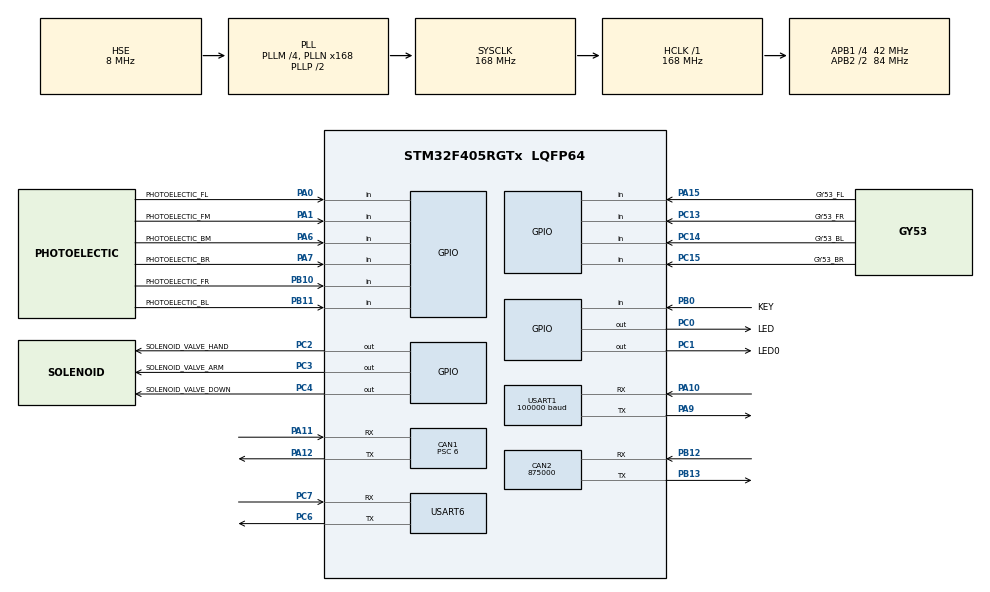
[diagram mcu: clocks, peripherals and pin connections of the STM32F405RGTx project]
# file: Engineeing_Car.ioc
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CAN1.BS1=CAN_BS1_3TQ
CAN1.BS2=CAN_BS2_4TQ
CAN1.CalculateBaudRate=875000
CAN1.CalculateTimeBit=1142.85
CAN1.CalculateTimeQuantum=142.85714285714286
CAN1.Mode=CAN_MODE_NORMAL
CAN1.NART=ENABLE
CAN1.Prescaler=6
CAN1.SJW=CAN_SJW_1TQ
CAN2.CalculateBaudRate=875000
CAN2.CalculateTimeBit=1142.85
CAN2.CalculateTimeQuantum=380.95238095238096
Dma.Request0=USART1_RX
Dma.Request1=USART6_TX
Dma.Request2=USART6_RX
Dma.USART1_RX.0.Direction=DMA_PERIPH_TO_MEMORY
Dma.USART1_RX.0.FIFOMode=DMA_FIFOMODE_DISABLE
Dma.USART1_RX.0.Instance=DMA2_Stream2
Dma.USART1_RX.0.MemDataAlignment=DMA_MDATAALIGN_BYTE
Dma.USART1_RX.0.MemInc=DMA_MINC_ENABLE
Dma.USART1_RX.0.Mode=DMA_NORMAL
Dma.USART1_RX.0.PeriphDataAlignment=DMA_PDATAALIGN_BYTE
Dma.USART1_RX.0.PeriphInc=DMA_PINC_DISABLE
Dma.USART1_RX.0.Priority=DMA_PRIORITY_VERY_HIGH
Dma.USART6_RX.2.Direction=DMA_PERIPH_TO_MEMORY
Dma.USART6_RX.2.FIFOMode=DMA_FIFOMODE_DISABLE
Dma.USART6_RX.2.Instance=DMA2_Stream1
Dma.USART6_RX.2.MemDataAlignment=DMA_MDATAALIGN_BYTE
Dma.USART6_RX.2.MemInc=DMA_MINC_ENABLE
Dma.USART6_RX.2.Mode=DMA_NORMAL
Dma.USART6_RX.2.PeriphDataAlignment=DMA_PDATAALIGN_BYTE
Dma.USART6_RX.2.PeriphInc=DMA_PINC_DISABLE
Dma.USART6_RX.2.Priority=DMA_PRIORITY_LOW
Dma.USART6_TX.1.Direction=DMA_MEMORY_TO_PERIPH
Dma.USART6_TX.1.FIFOMode=DMA_FIFOMODE_DISABLE
Dma.USART6_TX.1.Instance=DMA2_Stream6
Dma.USART6_TX.1.MemDataAlignment=DMA_MDATAALIGN_BYTE
Dma.USART6_TX.1.MemInc=DMA_MINC_ENABLE
Dma.USART6_TX.1.Mode=DMA_NORMAL
Dma.USART6_TX.1.PeriphDataAlignment=DMA_PDATAALIGN_BYTE
Dma.USART6_TX.1.PeriphInc=DMA_PINC_DISABLE
Dma.USART6_TX.1.Priority=DMA_PRIORITY_HIGH
Mcu.Family=STM32F4
Mcu.Name=STM32F405RGTx
Mcu.Package=LQFP64
NVIC.CAN1_RX0_IRQn=true\:1\:0\:true\:false\:true\:true\:true
NVIC.CAN2_RX0_IRQn=true\:0\:0\:false\:false\:true\:true\:true
NVIC.DMA2_Stream1_IRQn=true\:0\:0\:false\:false\:true\:false\:true
NVIC.DMA2_Stream2_IRQn=true\:0\:0\:false\:false\:true\:false\:true
NVIC.DMA2_Stream6_IRQn=true\:0\:0\:false\:false\:true\:false\:true
NVIC.PriorityGroup=NVIC_PRIORITYGROUP_4
NVIC.TIM2_IRQn=true\:0\:0\:false\:false\:true\:true\:true
NVIC.TIM3_IRQn=true\:0\:0\:false\:false\:true\:true\:true
NVIC.TIM4_IRQn=true\:0\:0\:false\:false\:true\:true\:true
PA0-WKUP.GPIO_Label=PHOTOELECTIC_FL
PA0-WKUP.GPIO_PuPd=GPIO_PULLUP
PA0-WKUP.Signal=GPIO_Input
PA1.GPIO_Label=PHOTOELECTIC_FM
PA1.GPIO_PuPd=GPIO_PULLUP
PA1.Signal=GPIO_Input
PA10.Mode=Asynchronous
PA10.Signal=USART1_RX
PA11.Mode=CAN_Activate
PA11.Signal=CAN1_RX
PA12.Mode=CAN_Activate
PA12.Signal=CAN1_TX
PA15.GPIO_Label=GY53_FL
PA15.GPIO_PuPd=GPIO_PULLUP
PA15.Signal=GPIO_Input
PA6.GPIO_Label=PHOTOELECTIC_BM
PA6.GPIO_PuPd=GPIO_PULLUP
PA6.Signal=GPIO_Input
PA7.GPIO_Label=PHOTOELECTIC_BR
PA7.GPIO_PuPd=GPIO_PULLUP
PA7.Signal=GPIO_Input
PA9.Mode=Asynchronous
PA9.Signal=USART1_TX
PB0.GPIO_Label=KEY
PB0.GPIO_PuPd=GPIO_PULLUP
PB0.Signal=GPIO_Input
PB10.GPIO_Label=PHOTOELECTIC_FR
PB10.GPIO_PuPd=GPIO_PULLUP
PB10.Signal=GPIO_Input
PB11.GPIO_Label=PHOTOELECTIC_BL
PB11.GPIO_PuPd=GPIO_PULLUP
PB11.Signal=GPIO_Input
PB12.Mode=CAN_Activate
PB12.Signal=CAN2_RX
PB13.Mode=CAN_Activate
PB13.Signal=CAN2_TX
PC0.GPIO_Label=LED
PC0.GPIO_PuPd=GPIO_PULLDOWN
PC0.GPIO_Speed=GPIO_SPEED_FREQ_HIGH
PC0.PinState=GPIO_PIN_RESET
PC0.Signal=GPIO_Output
PC1.GPIO_Label=LED0
PC1.GPIO_PuPd=GPIO_PULLDOWN
PC1.GPIO_Speed=GPIO_SPEED_FREQ_HIGH
PC1.Signal=GPIO_Output
PC13-ANTI_TAMP.GPIO_Label=GY53_FR
PC13-ANTI_TAMP.GPIO_PuPd=GPIO_PULLUP
PC13-ANTI_TAMP.Signal=GPIO_Input
PC14-OSC32_IN.GPIO_Label=GY53_BL
PC14-OSC32_IN.GPIO_PuPd=GPIO_PULLUP
PC14-OSC32_IN.Signal=GPIO_Input
PC15-OSC32_OUT.GPIO_Label=GY53_BR
PC15-OSC32_OUT.GPIO_PuPd=GPIO_PULLUP
PC15-OSC32_OUT.Signal=GPIO_Input
PC2.GPIO_Label=SOLENOID_VALVE_HAND
PC2.GPIO_PuPd=GPIO_PULLDOWN
PC2.GPIO_Speed=GPIO_SPEED_FREQ_HIGH
PC2.Signal=GPIO_Output
PC3.GPIO_Label=SOLENOID_VALVE_ARM
PC3.GPIO_PuPd=GPIO_PULLDOWN
PC3.GPIO_Speed=GPIO_SPEED_FREQ_HIGH
PC3.Signal=GPIO_Output
PC4.GPIO_Label=SOLENOID_VALVE_DOWN
PC4.GPIO_PuPd=GPIO_PULLDOWN
PC4.GPIO_Speed=GPIO_SPEED_FREQ_HIGH
PC4.Signal=GPIO_Output
PC6.Mode=Asynchronous
PC6.Signal=USART6_TX
PC7.Mode=Asynchronous
PC7.Signal=USART6_RX
PH0-OSC_IN.Mode=HSE-External-Oscillator
PH0-OSC_IN.Signal=RCC_OSC_IN
PH1-OSC_OUT.Mode=HSE-External-Oscillator
PH1-OSC_OUT.Signal=RCC_OSC_OUT
ProjectManager.HeapSize=0x200
ProjectManager.StackSize=0x400
ProjectManager.TargetToolchain=MDK-ARM V5.27
RCC.48MHZClocksFreq_Value=84000000
RCC.AHBFreq_Value=168000000
RCC.APB1CLKDivider=RCC_HCLK_DIV4
RCC.APB1Freq_Value=42000000
RCC.APB1TimFreq_Value=84000000
RCC.APB2CLKDivider=RCC_HCLK_DIV2
RCC.APB2Freq_Value=84000000
RCC.APB2TimFreq_Value=168000000
RCC.CortexFreq_Value=168000000
RCC.HCLKFreq_Value=168000000
RCC.HSE_VALUE=8000000
RCC.HSI_VALUE=16000000
RCC.LSE_VALUE=32768
RCC.PLLM=4
RCC.PLLN=168
RCC.PLLSourceVirtual=RCC_PLLSOURCE_HSE
RCC.SYSCLKFreq_VALUE=168000000
RCC.SYSCLKSource=RCC_SYSCLKSOURCE_PLLCLK
RCC.VCOOutputFreq_Value=336000000
TIM2.AutoReloadPreload=TIM_AUTORELOAD_PRELOAD_ENABLE
TIM2.Period=1000-1
TIM2.Prescaler=84-1
TIM3.Period=7200-1
TIM3.Prescaler=10000-1
TIM4.Period=9999
TIM4.Prescaler=83
USART1.BaudRate=100000
USART1.Mode=MODE_RX
USART1.Parity=PARITY_EVEN
USART1.VirtualMode=VM_ASYNC
USART6.VirtualMode=VM_ASYNC
VP_IWDG_VS_IWDG.Mode=IWDG_Activate
VP_TIM2_VS_ClockSourceINT.Mode=Internal
VP_TIM3_VS_ClockSourceINT.Mode=Internal
VP_TIM4_VS_ClockSourceINT.Mode=Internal
board=custom

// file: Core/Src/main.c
/* USER CODE BEGIN Header */
/**
  ******************************************************************************
  * @file           : main.c
  * @brief          : Main program body
  ******************************************************************************
  * @attention
  *
  * <h2><center>&copy; Copyright (c) 2020 STMicroelectronics.
  * All rights reserved.</center></h2>
  *
  * This software component is licensed by ST under BSD 3-Clause license,
  * the "License"; You may not use this file except in compliance with the
  * License. You may obtain a copy of the License at:
  *                        opensource.org/licenses/BSD-3-Clause
  *
  ******************************************************************************
  */
/* USER CODE END Header */
#include "main.h"
#include "can.h"
#include "dma.h"
#include "iwdg.h"
#include "tim.h"
#include "usart.h"
#include "gpio.h"

/* USER CODE BEGIN Includes */
#include "robo_base.h"
#include "Remote.h"
/* USER CODE END Includes */

/* USER CODE BEGIN PV */
extern ROBO_BASE Robo_Base;
/* USER CODE END PV */

void SystemClock_Config(void);

int main(void)
{

  /* MCU Configuration--------------------------------------------------------*/

  /* Reset of all peripherals, Initializes the Flash interface and the Systick. */
  HAL_Init();

  /* USER CODE BEGIN Init */
	Usart_Init();
  /* USER CODE END Init */

  /* Configure the system clock */
  SystemClock_Config();

  /* Initialize all configured peripherals */
  MX_GPIO_Init();
  MX_DMA_Init();
  MX_CAN1_Init();
  MX_TIM2_Init();
  MX_USART1_UART_Init();
  MX_IWDG_Init();
  MX_CAN2_Init();
  MX_TIM3_Init();
  MX_TIM4_Init();
  MX_USART6_UART_Init();
  /* USER CODE BEGIN 2 */
	MX_IWDG_Init();
	BASE_Init(&Robo_Base);
	__HAL_UART_ENABLE_IT(&huart1,UART_IT_IDLE);
	HAL_TIM_Base_Start_IT(&htim2);
	CAN_FilterConfig();
  /* USER CODE END 2 */

  /* Infinite loop */
  while (1)
  {

  }
}

void SystemClock_Config(void)
{
  RCC_OscInitTypeDef RCC_OscInitStruct = {0};
  RCC_ClkInitTypeDef RCC_ClkInitStruct = {0};

  /** Configure the main internal regulator output voltage
  */
  __HAL_RCC_PWR_CLK_ENABLE();
  __HAL_PWR_VOLTAGESCALING_CONFIG(PWR_REGULATOR_VOLTAGE_SCALE1);
  /** Initializes the RCC Oscillators according to the specified parameters
  * in the RCC_OscInitTypeDef structure.
  */
  RCC_OscInitStruct.OscillatorType = RCC_OSCILLATORTYPE_LSI|RCC_OSCILLATORTYPE_HSE;
  RCC_OscInitStruct.HSEState = RCC_HSE_ON;
  RCC_OscInitStruct.LSIState = RCC_LSI_ON;
  RCC_OscInitStruct.PLL.PLLState = RCC_PLL_ON;
  RCC_OscInitStruct.PLL.PLLSource = RCC_PLLSOURCE_HSE;
  RCC_OscInitStruct.PLL.PLLM = 4;
  RCC_OscInitStruct.PLL.PLLN = 168;
  RCC_OscInitStruct.PLL.PLLP = RCC_PLLP_DIV2;
  RCC_OscInitStruct.PLL.PLLQ = 4;
  if (HAL_RCC_OscConfig(&RCC_OscInitStruct) != HAL_OK)
  {
    Error_Handler();
  }
  /** Initializes the CPU, AHB and APB buses clocks
  */
  RCC_ClkInitStruct.ClockType = RCC_CLOCKTYPE_HCLK|RCC_CLOCKTYPE_SYSCLK
                              |RCC_CLOCKTYPE_PCLK1|RCC_CLOCKTYPE_PCLK2;
  RCC_ClkInitStruct.SYSCLKSource = RCC_SYSCLKSOURCE_PLLCLK;
  RCC_ClkInitStruct.AHBCLKDivider = RCC_SYSCLK_DIV1;
  RCC_ClkInitStruct.APB1CLKDivider = RCC_HCLK_DIV4;
  RCC_ClkInitStruct.APB2CLKDivider = RCC_HCLK_DIV2;

  if (HAL_RCC_ClockConfig(&RCC_ClkInitStruct, FLASH_LATENCY_5) != HAL_OK)
  {
    Error_Handler();
  }
}

void Error_Handler(void)
{
  __disable_irq();
  while (1)
  {
  }
}

/************************ (C) COPYRIGHT STMicroelectronics *****END OF FILE****/
